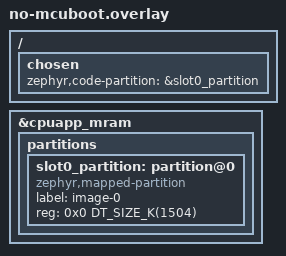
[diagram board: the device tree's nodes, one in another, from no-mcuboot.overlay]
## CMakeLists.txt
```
#
# Copyright (c) 2022 Nordic Semiconductor ASA
#
# SPDX-License-Identifier: LicenseRef-Nordic-5-Clause
#

cmake_minimum_required(VERSION 3.20.0)

find_package(Zephyr REQUIRED HINTS $ENV{ZEPHYR_BASE})
project(nrf_cloud)

# Include certs files if enabled.
zephyr_include_directories_ifdef(CONFIG_NRF_CLOUD_PROVISION_CERTIFICATES certs)

# NORDIC SDK APP START
target_sources(app PRIVATE src/main.c)
target_sources(app PRIVATE src/application.c)
target_sources(app PRIVATE src/cloud_connection.c)
target_sources(app PRIVATE src/message_queue.c)
target_sources(app PRIVATE src/temperature.c)
target_sources(app PRIVATE src/fota_support.c)
target_sources(app PRIVATE src/led_control.c)
target_sources(app PRIVATE src/sample_reboot.c)
target_sources(app PRIVATE src/shadow_config.c)

if(CONFIG_LOCATION_TRACKING)
  target_sources(app PRIVATE src/location_tracking.c)
endif()

if(CONFIG_COAP_SHADOW)
  target_sources(app PRIVATE src/shadow_support_coap.c)
endif()

if(CONFIG_COAP_FOTA)
  target_sources(app PRIVATE src/fota_support_coap.c)
endif()

if(CONFIG_NRF_PROVISIONING)
  target_sources(app PRIVATE src/provisioning_support.c)
endif()

# NORDIC SDK APP END

zephyr_include_directories(src)
zephyr_include_directories(config)
```

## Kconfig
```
#
# Copyright (c) 2022 Nordic Semiconductor ASA
#
# SPDX-License-Identifier: LicenseRef-Nordic-5-Clause
#

menu "Wi-Fi nRF Cloud sample settings"

config APP_VERSION
	string "Wi-Fi nRF Cloud sample version"
	default "1.0.0"

config CLOUD_CONNECTION_RETRY_TIMEOUT_SECONDS
	int "Cloud connection retry timeout (seconds)"
	default 30
	help
	  If connecting to nRF Cloud takes longer than this timeout, it will be
	  reattempted.

config WIFI_CONNECT_RETRY_TIMEOUT_SECONDS
	int "Wi-Fi connection retry timeout (seconds)"
	default 10
	help
	  If a Wi-Fi connection attempt fails, or an established connection is
	  lost, wait this many seconds before requesting a (re)connection.

config CLOUD_READY_TIMEOUT_SECONDS
	int "Cloud readiness timeout (seconds)"
	default 600
	help
	  If the connection to nRF Cloud does not become ready within this
	  timeout, the sample will reset its connection and try again.

config DATE_TIME_ESTABLISHMENT_TIMEOUT_SECONDS
	int "Date and time establishment timeout (seconds)"
	default 300
	help
	  The sample will wait this many seconds for the device to determine the
	  current date and time before giving up and moving on.

config APPLICATION_THREAD_STACK_SIZE
	int "Application Thread Stack Size (bytes)"
	default 2048
	help
	  Sets the stack size (in bytes) for the application thread of the
	  sample.

config CONNECTION_THREAD_STACK_SIZE
	int "Connection Thread Stack Size (bytes)"
	default 2048
	help
	  Sets the stack size (in bytes) for the connection thread of the
	  sample.

config MESSAGE_THREAD_STACK_SIZE
	int "Message Queue Thread Stack Size (bytes)"
	default 2048
	help
	  Sets the stack size (in bytes) for the message queue processing
	  thread of the sample.

config LED_THREAD_STACK_SIZE
	int "LED Thread Stack Size (bytes)"
	default 1024
	help
	  Sets the stack size (in bytes) for the LED thread.

config MAX_OUTGOING_MESSAGES
	int "Outgoing message maximum"
	default 25
	help
	  Sets the maximum number of device messages which may be enqueued
	  before further messages are dropped.
	  Increasing this value may require an increase to CONFIG_HEAP_MEM_POOL_SIZE.

config MAX_CONSECUTIVE_SEND_FAILURES
	int "Max outgoing consecutive send failures"
	default 5
	help
	  Sets the maximum number of device messages which may fail to send
	  before a connection reset and cooldown is triggered.

config CONSECUTIVE_SEND_FAILURE_COOLDOWN_SECONDS
	int "Cooldown after max consecutive send failures exceeded"
	default 10
	help
	  If a connection reset is triggered by too many failed device
	  messages, the sample will wait this long (in seconds) before trying
	  again.

config SENSOR_SAMPLE_INTERVAL_SECONDS
	int "Sensor sampling interval (seconds)"
	default 60
	help
	  Sets the time to wait between each sensor sample.

menuconfig LOCATION_TRACKING
	bool "Location tracking service"
	default y
	help
	  Uses Wi-Fi information to determine and report device location.

if LOCATION_TRACKING

config LOCATION_TRACKING_SAMPLE_INTERVAL_SECONDS
	int "Location sampling interval (seconds)"
	default 60
	help
	  Sets the location sampling interval in seconds.

endif

config TEMP_TRACKING
	bool "Track temperature"
	default y
	help
	  Sets whether to take temperature measurements.

config TEMP_ALERT_LIMIT
	int "Temperature limit to print alert"
	default 30
	help
	  Sets the temperature in degrees C over which a temperature alert will
	  be printed through serial terminal.

choice
	prompt "LED indication"
	default LED_INDICATION_GPIO if $(dt_compat_enabled,gpio-leds)
	default LED_INDICATION_DISABLED

config LED_INDICATION_GPIO
	bool "Enable LED indication using the gpio-leds driver"
	select LED
	select LED_GPIO

config LED_INDICATION_DISABLED
	bool "Disable LED indication"

endchoice

choice
	prompt "LED indication LED type"
	depends on !LED_INDICATION_DISABLED
	default LED_INDICATOR_4LED if !LED_INDICATION_DISABLED
	default LED_INDICATOR_NONE

config LED_INDICATOR_4LED
	bool "Four binary LEDs"
	depends on !LED_INDICATION_DISABLED

config LED_INDICATOR_NONE
	bool "No indicator LEDs"
	depends on LED_INDICATION_DISABLED

endchoice

config LED_VERBOSE_INDICATION
	bool "Enables extra LED status indications"
	depends on !LED_INDICATION_DISABLED
	default y

config LED_CONTINUOUS_INDICATION
	bool "Show an idle pattern instead of turning LEDs off"
	depends on !LED_INDICATION_DISABLED
	default y

config TEST_COUNTER
	bool "Sets whether the test counter is enabled"
	help
	  When enabled, the test counter configuration setting in the shadow is ignored.

config TEST_COUNTER_MULTIPLIER
	int "The number of test counter messages sent on each update"
	default 1
	range 1 1000
	help
	  This is a way to increase the number of device messages sent by the sample.
	  It is useful for load testing.

if NRF_CLOUD_COAP

menuconfig COAP_SHADOW
	bool "Updating shadow service"
	default y
	help
	  Updates the shadow with device information. Checks for a shadow
	  delta periodically and processes it if received.

if COAP_SHADOW

config COAP_SHADOW_CHECK_RATE_SECONDS
	int "Shadow job check interval (seconds)"
	default 300
	help
	  Sets the time to wait between each request to get any change to the
	  device shadow.

config COAP_SHADOW_THREAD_STACK_SIZE
	int "CoAP Shadow Thread Stack Size (bytes)"
	default 3072
	help
	  Sets the stack size (in bytes) for the CoAP shadow thread of the
	  sample.

endif

config COAP_SEND_CONFIRMABLE
	bool "Send device messages as confirmable"
	help
	  Ensures all CoAP transfers, even for often less important messages such
	  as sensor data, are sent as confirmable messages.

endif

endmenu

if NRF_CLOUD_MQTT
module-str = MQTT nRF Cloud
endif
if NRF_CLOUD_COAP
module-str = CoAP nRF Cloud
endif
module = WIFI_NRF_CLOUD
source "$(ZEPHYR_BASE)/subsys/logging/Kconfig.template.log_config"

menu "Zephyr Kernel"
source "Kconfig.zephyr"
endmenu
```

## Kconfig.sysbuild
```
#
# Copyright (c) 2024 Nordic Semiconductor
#
# SPDX-License-Identifier: LicenseRef-Nordic-5-Clause
#

config WIFI_NRF70
	default y if BOARD_NRF7002DK_NRF5340_CPUAPP_NS || \
		BOARD_NRF54L15DK_NRF54L15_CPUAPP || \
		BOARD_NRF54H20DK_NRF54H20_CPUAPP || \
		BOARD_NRF5340DK_NRF5340_CPUAPP_NS || \
		BOARD_NRF54LM20DK_NRF54LM20A_CPUAPP || \
		BOARD_NRF54LM20DK_NRF54LM20B_CPUAPP

source "share/sysbuild/Kconfig"
```

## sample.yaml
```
sample:
  name: Wi-Fi nRF Cloud Sample
tests:
  sample.wifi.conn.mqtt:
    sysbuild: true
    build_only: true
    integration_platforms:
      - nrf7002dk/nrf5340/cpuapp/ns
      - nrf7120dk/nrf7120/cpuapp/ns
    platform_allow:
      - nrf7002dk/nrf5340/cpuapp/ns
      - nrf7120dk/nrf7120/cpuapp/ns
    extra_args:
      - EXTRA_CONF_FILE="mqtt.conf"
    tags:
      - ci_build
      - sysbuild
      - ci_samples_wifi
  sample.wifi.conn.coap.nofota:
    sysbuild: true
    build_only: true
    integration_platforms:
      - nrf7120dk/nrf7120/cpuapp/ns
    platform_allow:
      - nrf7120dk/nrf7120/cpuapp/ns
    extra_args:
      - EXTRA_CONF_FILE="coap.conf"
    tags:
      - ci_build
      - sysbuild
      - ci_samples_wifi
  # Secure-only (no /ns), no FOTA (coap.conf without coap-fota.conf) and no
  # MCUboot (SB_CONFIG_BOOTLOADER_NONE overrides Kconfig.sysbuild's default
  # of MCUboot for this board target). no-mcuboot.overlay is required: the
  # board's default partition layout reserves the first 64 KB of MRAM for
  # MCUboot and links the app to run from slot0_partition at 0x10000, which
  # only works if MCUboot is actually present at 0x0 to jump there. See the
  # overlay file for details.
  sample.wifi.conn.coap.sonly.nofota:
    sysbuild: true
    build_only: true
    integration_platforms:
      - nrf7120dk/nrf7120/cpuapp
    platform_allow:
      - nrf7120dk/nrf7120/cpuapp
    extra_args:
      - EXTRA_CONF_FILE="coap.conf"
      - SB_CONFIG_BOOTLOADER_NONE=y
      - DTC_OVERLAY_FILE="no-mcuboot.overlay"
    tags:
      - ci_build
      - sysbuild
      - ci_samples_wifi
  sample.wifi.conn.coap:
    sysbuild: true
    build_only: true
    integration_platforms:
      - nrf7002dk/nrf5340/cpuapp/ns
      - nrf7120dk/nrf7120/cpuapp
    platform_allow:
      - nrf7002dk/nrf5340/cpuapp/ns
      - nrf7120dk/nrf7120/cpuapp
    extra_args:
      - EXTRA_CONF_FILE="coap.conf;coap-fota.conf"
    tags:
      - ci_build
      - sysbuild
      - ci_samples_wifi
  sample.wifi.conn.nrf7002eb2.mqtt:
    sysbuild: true
    build_only: true
    integration_platforms:
      - nrf54lm20dk/nrf54lm20a/cpuapp/ns
      - nrf54lm20dk/nrf54lm20b/cpuapp/ns
    platform_allow:
      - nrf54lm20dk/nrf54lm20a/cpuapp/ns
      - nrf54lm20dk/nrf54lm20b/cpuapp/ns
    extra_args:
      - SHIELD=nrf7002eb2
      - EXTRA_CONF_FILE="mqtt.conf"
    tags:
      - ci_build
      - sysbuild
      - ci_samples_wifi
  sample.wifi.conn.nrf7002eb2.coap:
    sysbuild: true
    build_only: true
    integration_platforms:
      - nrf54lm20dk/nrf54lm20a/cpuapp/ns
      - nrf54lm20dk/nrf54lm20b/cpuapp/ns
    platform_allow:
      - nrf54lm20dk/nrf54lm20a/cpuapp/ns
      - nrf54lm20dk/nrf54lm20b/cpuapp/ns
    extra_args:
      - SHIELD=nrf7002eb2
      - EXTRA_CONF_FILE="coap.conf;coap-fota.conf"
    tags:
      - ci_build
      - sysbuild
      - ci_samples_wifi
```

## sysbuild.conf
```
#
# Copyright (c) 2024 Nordic Semiconductor
#
# SPDX-License-Identifier: LicenseRef-Nordic-5-Clause
#

# Save flash
SB_CONFIG_BOOTLOADER_NONE=y
SB_CONFIG_BOOTLOADER_MCUBOOT=n
```

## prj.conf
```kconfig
#
# Copyright (c) 2022 Nordic Semiconductor ASA
#
# SPDX-License-Identifier: LicenseRef-Nordic-5-Clause
#

# Log level
# For more verbose and detailed log output, set the log level to
# CONFIG_WIFI_NRF_CLOUD_LOG_LEVEL_DBG=y instead.
CONFIG_WIFI_NRF_CLOUD_LOG_LEVEL_INF=y

# General config
CONFIG_EVENTS=y
CONFIG_PICOLIBC_IO_FLOAT=y
CONFIG_RESET_ON_FATAL_ERROR=y
CONFIG_NCS_SAMPLES_DEFAULTS=y
CONFIG_DK_LIBRARY=y

# Improved Logging
# CONFIG_LOG_MODE_DEFERRED allows logging from multiple threads simultaneously without creating
# splintered log entries, at the cost of needing a buffer for storing logs.
CONFIG_LOG_MODE_DEFERRED=y

# CONFIG_LOG_BUFFER_SIZE is the aforementioned buffer. A size of 4096 bytes is useful for debugging
# and prototyping, but is probably more than necessary for production-ready firmware.
CONFIG_LOG_BUFFER_SIZE=4096

# Heap and stacks
# Extended memory heap size needed for Wi-Fi operation and encoding JSON-based nRF Cloud Device Messages.
# Add 256 bytes for each additional scanning result (CONFIG_NRF_WIFI_SCAN_MAX_BSS_CNT),
# assuming sane SSID lengths.
CONFIG_HEAP_MEM_POOL_SIZE=40144
CONFIG_HEAP_MEM_POOL_IGNORE_MIN=y
CONFIG_SYSTEM_WORKQUEUE_STACK_SIZE=4096
CONFIG_MAIN_STACK_SIZE=2048

# Enable Networking and Connection Manager.
CONFIG_NETWORKING=y
CONFIG_NET_SOCKETS=y
CONFIG_NET_SOCKETS_OFFLOAD=n
CONFIG_NET_MGMT_EVENT_QUEUE_SIZE=30
CONFIG_NET_CONNECTION_MANAGER_MONITOR_STACK_SIZE=6144
CONFIG_NET_CONNECTION_MANAGER=y

CONFIG_NET_IPV4=y
CONFIG_NET_IPV6=y
CONFIG_NET_IPV6_NBR_CACHE=n
CONFIG_NET_IPV6_MLD=n

# DNS
CONFIG_DNS_RESOLVER=y
CONFIG_NET_SOCKETS_DNS_TIMEOUT=30000

# Wi-Fi drivers (nRF70x)
CONFIG_WIFI=y
CONFIG_WIFI_NRF70=y
CONFIG_WIFI_NRF70_SKIP_LOCAL_ADMIN_MAC=y

# Wi-Fi conn_mgr bindings
CONFIG_L2_WIFI_CONNECTIVITY=y
CONFIG_L2_WIFI_CONNECTIVITY_AUTO_CONNECT=y

# Wi-Fi credentials (simplified Wi-Fi connection setup)
CONFIG_WIFI_CREDENTIALS=y

# Wi-Fi networking and native networking stack
# Note: WIFI_NM_WPA_SUPPLICANT requires 24kB of unused RAM in the final build.
# Memory allocations are fine-tuned with that fact in mind.
CONFIG_WIFI_NM_WPA_SUPPLICANT=y
CONFIG_NET_L2_ETHERNET=y
CONFIG_NET_NATIVE=y
CONFIG_NET_SOCKETS_SOCKOPT_TLS=y
CONFIG_NET_CONTEXT_SNDTIMEO=y
CONFIG_NET_TCP=y
CONFIG_NET_DHCPV4=y

# MBEDTLS base configuration for Wi-Fi TLS/DTLS
CONFIG_MBEDTLS=y
CONFIG_MBEDTLS_ENABLE_HEAP=y
CONFIG_MBEDTLS_SSL_SERVER_NAME_INDICATION=y
CONFIG_MBEDTLS_HEAP_SIZE=80000
# PEM parsing is required for TLS credentials provisioned via the shell
CONFIG_MBEDTLS_PEM_PARSE_C=y
# Ciphersuite for MQTT
CONFIG_MBEDTLS_CIPHERSUITE_TLS_ECDHE_RSA_WITH_AES_128_CBC_SHA256=y
CONFIG_PSA_WANT_ALG_ECDSA=y
# PBKDF2-HMAC is needed for WPA2-PSK passphrase hashing (pbkdf2_sha1)
CONFIG_PSA_WANT_ALG_PBKDF2_HMAC=y
CONFIG_PSA_WANT_ALG_PBKDF2_AES_CMAC_PRF_128=y

# Wait for credential installation to be complete before connecting to nRF Cloud
CONFIG_NRF_CLOUD_CHECK_CREDENTIALS=y

# nRF Cloud
CONFIG_NRF_CLOUD=y
CONFIG_NRF_CLOUD_MQTT=y

# Use compile-time client ID for nRF Cloud
CONFIG_NRF_CLOUD_CLIENT_ID_SRC_HW_ID=y
CONFIG_HW_ID_LIBRARY=y
CONFIG_HW_ID_LIBRARY_SOURCE_DEVICE_ID=y

# Location Services configuration
CONFIG_LOCATION=y
CONFIG_NRF_CLOUD_LOCATION=y
CONFIG_LOCATION_METHOD_WIFI=y
# Keep CONFIG_NRF_WIFI_SCAN_MAX_BSS_CNT and CONFIG_LOCATION_METHOD_WIFI_SCANNING_RESULTS_MAX_CNT
# set to the same value.
CONFIG_NRF_WIFI_SCAN_MAX_BSS_CNT=10
CONFIG_LOCATION_METHOD_WIFI_SCANNING_RESULTS_MAX_CNT=10

# Date Time lib - Used by main application
CONFIG_DATE_TIME=y
# Enable date_time retries for Wi-Fi
# This prevents occasional DNS lookup flukes from
# rendering the device unable to connect until the next
# CONFIG_DATE_TIME_UPDATE_INTERVAL_SECONDS elapses (default 4 hours)
CONFIG_DATE_TIME_RETRY_COUNT=5
# Use a really short retry interval for demo purposes
# 60 seconds to 15 minutes is probably more appropriate for real-world applications
CONFIG_DATE_TIME_RETRY_INTERVAL_SECONDS=20

# Settings - NVS is used (required by WIFI_CREDENTIALS)
CONFIG_SETTINGS=y
CONFIG_SETTINGS_NVS=y
CONFIG_NVS=y

# Flash
CONFIG_FLASH=y
CONFIG_FLASH_PAGE_LAYOUT=y
CONFIG_FLASH_MAP=y

# TFM and Trusted Execution (required for Protected Storage credential management)
# Note: even when using Protected Storage, credentials are still retrieved into insecure
# memory when in use.
CONFIG_BUILD_WITH_TFM=y
CONFIG_TRUSTED_EXECUTION_NONSECURE=y
CONFIG_TFM_PARTITION_PROTECTED_STORAGE=y
# The NOT_SET profile enables all features; we reduce some settings below to save flash and RAM.
CONFIG_TFM_PROFILE_TYPE_NOT_SET=y
CONFIG_TFM_CRYPTO_ASYM_SIGN_MODULE_ENABLED=y

# Credential management shells
CONFIG_SHELL=y
CONFIG_NET_L2_WIFI_SHELL=y
CONFIG_WIFI_CREDENTIALS_SHELL=y
CONFIG_TLS_CREDENTIALS_SHELL=y
# "net iface" shows MAC + IP; "net ping" useful for connectivity checks
CONFIG_NET_SHELL=y
CONFIG_DEVMEM_SHELL=n
CONFIG_TLS_CREDENTIALS_BACKEND_PROTECTED_STORAGE=y
# Increased stack size needed for wifi_cred auto_connect command
CONFIG_SHELL_STACK_SIZE=6144
# nRFCloud credentials can exceed 1024 bytes
CONFIG_TLS_CREDENTIALS_SHELL_CRED_BUF_SIZE=3072
# Needed by the TLS credentials shell
CONFIG_BASE64=y

# Miscellaneous resource allocation tweaks needed to support Wi-Fi
CONFIG_MESSAGE_THREAD_STACK_SIZE=2048
CONFIG_CONNECTION_THREAD_STACK_SIZE=6144
CONFIG_DATE_TIME_THREAD_STACK_SIZE=2048
CONFIG_NET_TX_STACK_SIZE=1024
CONFIG_NET_RX_STACK_SIZE=2048
CONFIG_WIFI_NM_WPA_SUPPLICANT_THREAD_STACK_SIZE=6144
CONFIG_LOCATION_WORKQUEUE_STACK_SIZE=2048
CONFIG_ZVFS_POLL_MAX=8

## TF-M: keep IPC mode (default) for the MQTT build. Enable MM-IOVEC to save RAM.
CONFIG_TFM_PSA_FRAMEWORK_HAS_MM_IOVEC=y

## Re-enable IPv6 neighbor cache and MLD (disabled above by default)
CONFIG_NET_IPV6_NBR_CACHE=y
CONFIG_NET_IPV6_MLD=y

## Configure MBEDTLS for MQTT/TLS (CoAP overlay overrides these)
CONFIG_MQTT_LIB_TLS=y
CONFIG_MBEDTLS_SSL_SRV_C=n
CONFIG_MBEDTLS_SSL_COOKIE_C=n

## nRF700x memory allocation (CoAP overlay overrides these)
CONFIG_NRF_WIFI_CTRL_HEAP_SIZE=15000
CONFIG_NRF_WIFI_DATA_HEAP_SIZE=97856

## Thread stack sizes (CoAP overlay overrides APPLICATION_THREAD, NET_MGMT_EVENT, CONNECTION_THREAD)
CONFIG_APPLICATION_THREAD_STACK_SIZE=2048
CONFIG_NET_MGMT_EVENT_STACK_SIZE=8192

# Enable key generation for nRF Cloud credentials on device, and the associated shell command.
CONFIG_NRF_CLOUD_CREDENTIALS_KEYGEN=y
CONFIG_NRF_CLOUD_CREDENTIALS_KEYGEN_SHELL=y
```

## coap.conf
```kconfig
#
# Copyright (c) 2024 Nordic Semiconductor ASA
#
# SPDX-License-Identifier: LicenseRef-Nordic-5-Clause
#

## TF-M: SFN mode with MM-IOVEC (see prj.conf) to keep RAM usage down for CoAP.
CONFIG_TFM_IPC=n
CONFIG_TFM_SFN=y
CONFIG_TFM_CRYPTO_CONC_OPER_NUM=4

## Additional date_time settings for CoAP
CONFIG_DATE_TIME_NTP=y
CONFIG_DATE_TIME_LOG_LEVEL_DBG=y

## Configure MBEDTLS for CoAP/DTLS
CONFIG_MQTT_LIB_TLS=n
CONFIG_MBEDTLS_DTLS=y
CONFIG_MBEDTLS_SSL_SRV_C=y
CONFIG_MBEDTLS_SSL_COOKIE_C=y
# Ciphersuite for CoAP
CONFIG_MBEDTLS_CIPHERSUITE_TLS_ECDHE_ECDSA_WITH_AES_128_GCM_SHA256=y
CONFIG_MBEDTLS_SSL_DTLS_HELLO_VERIFY=y
CONFIG_MBEDTLS_SSL_DTLS_CONNECTION_ID=y
CONFIG_NET_SOCKETS_ENABLE_DTLS=y

## Memory allocation
CONFIG_NRF_WIFI_CTRL_HEAP_SIZE=20000
CONFIG_NRF_WIFI_DATA_HEAP_SIZE=92856

## Thread stack sizes

CONFIG_APPLICATION_THREAD_STACK_SIZE=4096
CONFIG_CONNECTION_THREAD_STACK_SIZE=6144
CONFIG_NET_MGMT_EVENT_STACK_SIZE=8192
CONFIG_WIFI_NM_WPA_SUPPLICANT_THREAD_STACK_SIZE=6144
CONFIG_NET_CONNECTION_MANAGER_MONITOR_STACK_SIZE=5120
CONFIG_NET_TX_STACK_SIZE=1024
CONFIG_NET_RX_STACK_SIZE=2048
CONFIG_LOCATION_WORKQUEUE_STACK_SIZE=4096

# nRF Cloud: CoAP
CONFIG_NRF_CLOUD_MQTT=n
CONFIG_NRF_CLOUD_COAP=y
CONFIG_NRF_CLOUD_LOCATION=n
CONFIG_NRF_CLOUD_JWT_SOURCE_CUSTOM=y

# General config
CONFIG_FPU=y

# Rate of cloud interactions
# These are faster than one normally would use in a low power device.
# This is strictly for demo purposes.
CONFIG_SENSOR_SAMPLE_INTERVAL_SECONDS=120
CONFIG_LOCATION_TRACKING_SAMPLE_INTERVAL_SECONDS=360

# Logs
CONFIG_NET_LOG=y
CONFIG_LOG_PRINTK=y
CONFIG_COAP_LOG_LEVEL_INF=y
CONFIG_LOCATION_LOG_LEVEL_INF=y

# Network
CONFIG_POSIX_API=y
CONFIG_NET_SOCKETS_TLS_SET_MAX_FRAGMENT_LENGTH=y
CONFIG_NET_SOCKETS_OFFLOAD_PRIORITY=40

# CoAP Client
CONFIG_COAP_CLIENT_BLOCK_SIZE=1024
CONFIG_COAP_CLIENT_STACK_SIZE=3072
CONFIG_COAP_CLIENT_THREAD_PRIORITY=0
CONFIG_COAP_EXTENDED_OPTIONS_LEN_VALUE=40
# Wi-Fi RTT to nRF Cloud can be high; give CON transfers more time.
CONFIG_COAP_INIT_ACK_TIMEOUT_MS=4000
CONFIG_COAP_MAX_RETRANSMIT=8

# Location Services configuration
CONFIG_LOCATION_DATA_DETAILS=n

CONFIG_TEMP_ALERT_LIMIT=24

# Disabling to prevent IPv6 error logs
CONFIG_NET_IPV6=n
CONFIG_NET_IPV6_NBR_CACHE=n
CONFIG_NET_IPV6_MLD=n
```

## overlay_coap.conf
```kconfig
#
# Copyright (c) 2024 Nordic Semiconductor ASA
#
# SPDX-License-Identifier: LicenseRef-Nordic-5-Clause
#

## Disable CoAP FOTA
CONFIG_COAP_FOTA=n

## TFM: select SFN mode for faster crypto in CoAP builds
CONFIG_TFM_IPC=n
CONFIG_TFM_SFN=y
CONFIG_TFM_CRYPTO_CONC_OPER_NUM=4

## Additional date_time settings for CoAP
CONFIG_DATE_TIME_NTP=y
CONFIG_DATE_TIME_LOG_LEVEL_DBG=y

## Configure MBEDTLS for CoAP/DTLS
CONFIG_MQTT_LIB_TLS=n
CONFIG_MBEDTLS_DTLS=y
CONFIG_MBEDTLS_SSL_SRV_C=y
CONFIG_MBEDTLS_SSL_COOKIE_C=y
CONFIG_MBEDTLS_SSL_DTLS_HELLO_VERIFY=y
CONFIG_MBEDTLS_SSL_DTLS_CONNECTION_ID=y
CONFIG_NET_SOCKETS_ENABLE_DTLS=y

# Keep legacy hostap crypto on nRF5340 NS Wi-Fi CoAP builds.
# If we use HOSTAP_CRYPTO_ALT_PSA, hostap selects MBEDTLS_USE_PSA_CRYPTO,
# which routes mbedTLS TLS/X.509 through PSA/TF-M and can break DTLS connect
# to coap.nrfcloud.com (observed as zsock_connect() failure: -111 / ECONNREFUSED).
# Legacy mode keeps the non-PSA mbedTLS TLS path and restores stable cloud connection.
CONFIG_HOSTAP_CRYPTO_ALT_LEGACY_PSA=y

## Memory allocation
CONFIG_NRF_WIFI_CTRL_HEAP_SIZE=20000
CONFIG_NRF_WIFI_DATA_HEAP_SIZE=92856

## Thread stack sizes
CONFIG_APPLICATION_THREAD_STACK_SIZE=8192
CONFIG_NET_MGMT_EVENT_STACK_SIZE=8000

# nRF Cloud: CoAP
CONFIG_NRF_CLOUD_MQTT=n
CONFIG_NRF_CLOUD_COAP=y
CONFIG_NRF_CLOUD_LOCATION=n
CONFIG_NRF_CLOUD_JWT_SOURCE_CUSTOM=y

# General config
CONFIG_FPU=y

# Rate of cloud interactions
# These are faster than one normally would use in a low power device.
# This is strictly for demo purposes.
CONFIG_SENSOR_SAMPLE_INTERVAL_SECONDS=120
CONFIG_LOCATION_TRACKING_SAMPLE_INTERVAL_SECONDS=360

# Logs
CONFIG_NET_LOG=y
CONFIG_LOG_PRINTK=y
CONFIG_COAP_LOG_LEVEL_INF=y
CONFIG_LOCATION_LOG_LEVEL_INF=y

# Network
CONFIG_POSIX_API=y
CONFIG_NET_SOCKETS_TLS_SET_MAX_FRAGMENT_LENGTH=y
CONFIG_NET_SOCKETS_OFFLOAD_PRIORITY=40

# CoAP Client
CONFIG_COAP_CLIENT_BLOCK_SIZE=1024
CONFIG_COAP_CLIENT_STACK_SIZE=6144
CONFIG_COAP_CLIENT_THREAD_PRIORITY=0
CONFIG_COAP_EXTENDED_OPTIONS_LEN_VALUE=40
# Wi-Fi RTT to nRF Cloud can be high; give CON transfers more time.
CONFIG_COAP_INIT_ACK_TIMEOUT_MS=4000
CONFIG_COAP_MAX_RETRANSMIT=8

# Location Services configuration
CONFIG_LOCATION_DATA_DETAILS=n

CONFIG_TEMP_ALERT_LIMIT=24

# Disabling to prevent IPv6 error logs
CONFIG_NET_IPV6=n
```

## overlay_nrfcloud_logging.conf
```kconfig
#
# Copyright (c) 2023 Nordic Semiconductor ASA
#
# SPDX-License-Identifier: LicenseRef-Nordic-5-Clause
#
CONFIG_NRF_CLOUD_LOG_BACKEND=y
CONFIG_NRF_CLOUD_LOG_OUTPUT_LEVEL=3
CONFIG_NRF_CLOUD_LOG_LOG_LEVEL_INF=y
CONFIG_LOG_MODE_DEFERRED=y
CONFIG_NRF_CLOUD_LOG_INCLUDE_LEVEL_0=y

# If enabled, log levels for each log source can be set per log backend, and
# can be changed dynamically.
CONFIG_LOG_RUNTIME_FILTERING=n

CONFIG_LOG_BUFFER_SIZE=4096

# Select which format to generate. Dictionary logs are compact but require
# decoding on the server or user PC. Text logs are verbose but immediately
# visible in the nRF Cloud web portal. Unless you disable UART text logging,
# you must set CONFIG_LOG_FMT_SECTION_STRIP=n when
# CONFIG_LOG_BACKEND_NRF_CLOUD_OUTPUT_DICTIONARY=y, or else you will get a
# build assert warning you to do so. This is to prevent a hard crash at runtime.
CONFIG_LOG_BACKEND_NRF_CLOUD_OUTPUT_TEXT=y
#CONFIG_LOG_BACKEND_NRF_CLOUD_OUTPUT_DICTIONARY=y
#CONFIG_LOG_FMT_SECTION_STRIP=n

CONFIG_LOG_PROCESS_THREAD_STACK_SIZE=4096
CONFIG_LOG_PROCESS_THREAD_SLEEP_MS=30000
```

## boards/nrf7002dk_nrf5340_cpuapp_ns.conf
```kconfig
#
# Copyright (c) 2026 Nordic Semiconductor ASA
#
# SPDX-License-Identifier: LicenseRef-Nordic-5-Clause
#

# nRF Cloud credentials
CONFIG_NRF_CLOUD_PROVISION_CERTIFICATES=y
CONFIG_NRF_CLOUD_CLIENT_ID_SRC_COMPILE_TIME=y
CONFIG_NRF_CLOUD_CLIENT_ID="216c393d-b529-4eb5-a2a7-987d5a8ae68a"

# Enable LTO to save flash memory (required for CoAP overlay which would otherwise overflow)
CONFIG_LTO=y
CONFIG_ISR_TABLES_LOCAL_DECLARATION=y
```

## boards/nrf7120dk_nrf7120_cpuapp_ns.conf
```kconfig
#
# Copyright (c) 2026 Nordic Semiconductor ASA
#
# SPDX-License-Identifier: LicenseRef-Nordic-5-Clause
#

# IOVEC would conflict with TFM_ITS_ENCRYPTED, which we want to keep
# as default for higher security.
CONFIG_TFM_PSA_FRAMEWORK_HAS_MM_IOVEC=n
# Necessary for TLS with MM-less IOVEC
CONFIG_TFM_CRYPTO_IOVEC_BUFFER_SIZE=36864
# pk_wrap.c uses PSA_ALG_ECDSA_ANY (pre-hashed ECDSA) for X.509 certificate
# chain verification
CONFIG_PSA_WANT_ALG_ECDSA_ANY=y

# FOTA requires MCUBoot; this sample uses BOOTLOADER_NONE on nrf7120dk.
# Disabling NRF_CLOUD_FOTA also avoids pulling in FW_INFO, which has no
# SOC_SERIES_NRF71 defaults and causes both a CMake and a linker error.
CONFIG_NRF_CLOUD_FOTA=n

# nRF7120 _ns/TF-M has no Zephyr flash driver (so no NVS), but it does have TF-M
# PSA secure storage. Use the PSA settings backend: settings are kept in RAM and
# persisted via TF-M PSA ITS, so settings init and the MQTT session-state save
# both succeed -- no need to disable settings or force a clean session.
CONFIG_SETTINGS_TFM_PSA=y
```

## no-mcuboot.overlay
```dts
/*
 * Copyright (c) 2026 Nordic Semiconductor ASA
 *
 * SPDX-License-Identifier: LicenseRef-Nordic-5-Clause
 */

/*
 * nrf7120dk/nrf7120/cpuapp's default partition layout (see
 * nordic/nrf7120_cpuapp_partition.dtsi) reserves the first 64 KB of MRAM for
 * MCUboot (boot_partition) and links the application to run from
 * slot0_partition at offset 0x10000. That only works with MCUboot actually
 * present at address 0 to jump into slot0 -- with
 * -DSB_CONFIG_BOOTLOADER_NONE=y no bootloader is built, so nothing would ever
 * reach the application at 0x10000 and the device would not boot.
 *
 * Merge boot_partition into slot0_partition so the single, non-upgradable
 * application image is linked to run directly from address 0x0 instead.
 * slot1_partition/storage_partition are untouched (slot0 still ends exactly
 * where slot1 begins, at 0x178000).
 *
 * Note: nrf7120dk_nrf7120_cpuapp_defconfig unconditionally sets
 * CONFIG_FLASH_LOAD_OFFSET=0xA000, a fixed SoC-level boot offset applied on
 * top of whatever address the code-partition starts at (regardless of
 * MCUboot). With this overlay the application therefore actually starts at
 * 0xA000 (0x0 + 0xA000), instead of 0x1A000 (0x10000 + 0xA000) as it would
 * without the overlay -- which lands inside the otherwise-empty
 * boot_partition gap and would never run without a bootloader there.
 */
/delete-node/ &boot_partition;
/delete-node/ &slot0_partition;

&cpuapp_mram {
	partitions {
		slot0_partition: partition@0 {
			compatible = "zephyr,mapped-partition";
			label = "image-0";
			reg = <0x0 DT_SIZE_K(1504)>;
		};
	};
};

/ {
	chosen {
		zephyr,code-partition = &slot0_partition;
	};
};
```

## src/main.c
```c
/* Copyright (c) 2023 Nordic Semiconductor ASA
 *
 * SPDX-License-Identifier: LicenseRef-Nordic-5-Clause
 */

#include <zephyr/kernel.h>
#include <stdio.h>
#include <zephyr/logging/log.h>
#include "application.h"
#include "cloud_connection.h"
#include "message_queue.h"
#include "led_control.h"
#if defined(CONFIG_NRF_CLOUD_COAP)
#include "fota_support_coap.h"
#include "shadow_support_coap.h"
#endif

LOG_MODULE_REGISTER(main, CONFIG_WIFI_NRF_CLOUD_LOG_LEVEL);

/* Here, we start the various threads that our application will run in */

#ifndef CONFIG_LED_INDICATION_DISABLED
/* Define, and automatically start the LED animation thread. See led_control.c */
K_THREAD_DEFINE(led_thread, CONFIG_LED_THREAD_STACK_SIZE, led_animation_thread_fn,
		NULL, NULL, NULL, 0, 0, 0);
#endif

/* Define, and automatically start the main application thread. See application.c */
K_THREAD_DEFINE(app_thread, CONFIG_APPLICATION_THREAD_STACK_SIZE, main_application_thread_fn,
		NULL, NULL, NULL, 0, 0, 0);

/* Define, and automatically start the message queue thread. See message_queue.c */
K_THREAD_DEFINE(msg_thread, CONFIG_MESSAGE_THREAD_STACK_SIZE, message_queue_thread_fn,
		NULL, NULL, NULL, 0, 0, 0);

/* Define, and automatically start the cloud connection thread. See cloud_connection.c */
K_THREAD_DEFINE(con_thread, CONFIG_CONNECTION_THREAD_STACK_SIZE, cloud_connection_thread_fn,
		NULL, NULL, NULL, 0, 0, 0);

#if defined(CONFIG_NRF_CLOUD_COAP)
#if defined(CONFIG_COAP_FOTA)
/* Define, and automatically start the CoAP FOTA check thread. See fota_support_coap.c */
K_THREAD_DEFINE(coap_fota, CONFIG_COAP_FOTA_THREAD_STACK_SIZE, coap_fota_thread_fn,
		NULL, NULL, NULL, 0, 0, 0);
#endif

#if defined(CONFIG_COAP_SHADOW)
/* Define, and automatically start the CoAP shadow check thread. See shadow_support_coap.c */
K_THREAD_DEFINE(coap_shadow, CONFIG_COAP_SHADOW_THREAD_STACK_SIZE, coap_shadow_thread_fn,
		NULL, NULL, NULL, 0, 0, 0);
#endif
#endif /* CONFIG_NRF_CLOUD_COAP */

/* main() is called from the main thread, which defaults to priority zero,
 * but for illustrative purposes we don't use it. main_application() could be called directly
 * from this function, rather than given its own dedicated thread.
 */
int main(void)
{
	const char *protocol;

	if (IS_ENABLED(CONFIG_NRF_CLOUD_MQTT)) {
		protocol = "MQTT";
	} else if (IS_ENABLED(CONFIG_NRF_CLOUD_COAP)) {
		protocol = "CoAP";
	}

	LOG_INF("WiFi nRF Cloud sample has started, version: %s, protocol: %s",
		CONFIG_APP_VERSION, protocol);

	return 0;
}
```

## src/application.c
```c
/* Copyright (c) 2023 Nordic Semiconductor ASA
 *
 * SPDX-License-Identifier: LicenseRef-Nordic-5-Clause
 */

#include <zephyr/kernel.h>
#include <zephyr/logging/log.h>
#include <zephyr/logging/log_ctrl.h>
#include <helpers/nrfx_reset_reason.h>
#include <date_time.h>
#include <stdio.h>
#include <net/nrf_cloud.h>
#include <net/nrf_cloud_codec.h>
#include <net/nrf_cloud_log.h>
#if defined(CONFIG_NRF_CLOUD_COAP)
#include <net/nrf_cloud_coap.h>
#endif
#if defined(CONFIG_LOCATION_TRACKING)
#include <modem/location.h>
#include "location_tracking.h"
#endif
#include <dk_buttons_and_leds.h>
#include "application.h"
#include "temperature.h"
#include "cloud_connection.h"
#include "message_queue.h"
#include "led_control.h"
#include "shadow_config.h"
#if IS_ENABLED(CONFIG_MEMFAULT) && IS_ENABLED(CONFIG_NRF_CLOUD_COAP)
#include <memfault/core/trace_event.h>
#endif

LOG_MODULE_REGISTER(application, CONFIG_WIFI_NRF_CLOUD_LOG_LEVEL);

/* Timer used to time the sensor sampling rate. */
static K_TIMER_DEFINE(sensor_sample_timer, NULL, NULL);

/* Temperature alert limits. */
#define TEMP_ALERT_LIMIT ((double)CONFIG_TEMP_ALERT_LIMIT)
#define TEMP_ALERT_HYSTERESIS 1.5
#define TEMP_ALERT_LOWER_LIMIT (TEMP_ALERT_LIMIT - TEMP_ALERT_HYSTERESIS)

/* State of the test counter. This can be changed using the configuration in the shadow */
static bool test_counter_enabled;

/**
 * @brief Construct a device message object with automatically generated timestamp
 *
 * The resultant JSON object will be conformal to the General Message Schema described in the
 * application-protocols repo:
 *
 * https://github.com/nRFCloud/application-protocols
 *
 * @param msg - The object to contain the message
 * @param appid - The appId for the device message
 * @param msg_type - The messageType for the device message
 * @return int - 0 on success, negative error code otherwise.
 */
static int create_timestamped_device_message(struct nrf_cloud_obj *const msg,
					     const char *const appid,
					     const char *const msg_type)
{
	int err;
	int64_t timestamp;

	/* Acquire timestamp */
	err = date_time_now(&timestamp);
	if (err) {
		LOG_ERR("Failed to obtain current time, error %d", err);
		return -ETIME;
	}

	/* Create message object */
	err = nrf_cloud_obj_msg_init(msg, appid,
				     IS_ENABLED(CONFIG_NRF_CLOUD_COAP) ? NULL : msg_type);
	if (err) {
		LOG_ERR("Failed to initialize message with appid %s and msg type %s",
			appid, msg_type);
		return err;
	}

	/* Add timestamp to message object */
	err = nrf_cloud_obj_ts_add(msg, timestamp);
	if (err) {
		LOG_ERR("Failed to add timestamp to data message with appid %s and msg type %s",
			appid, msg_type);
		nrf_cloud_obj_free(msg);
		return err;
	}

	return 0;
}

/**
 * @brief Transmit a collected sensor sample to nRF Cloud.
 *
 * @param sensor - The name of the sensor which was sampled.
 * @param value - The sampled sensor value.
 * @return int - 0 on success, negative error code otherwise.
 */
static int send_sensor_sample(const char *const sensor, double value)
{
	int ret;

	MSG_OBJ_DEFINE(msg_obj);

	/* Create a timestamped message container object for the sensor sample. */
	ret = create_timestamped_device_message(&msg_obj, sensor,
						NRF_CLOUD_JSON_MSG_TYPE_VAL_DATA);
	if (ret) {
		return -EINVAL;
	}

	/* Populate the container object with the sensor value. */
	ret = nrf_cloud_obj_num_add(&msg_obj, NRF_CLOUD_JSON_DATA_KEY, value, false);
	if (ret) {
		LOG_ERR("Failed to append value to %s sample container object ",
			sensor);
		nrf_cloud_obj_free(&msg_obj);
		return -ENOMEM;
	}

	/* Send the sensor sample container object as a device message. */
	return send_device_message(&msg_obj);
}

#if defined(CONFIG_LOCATION_TRACKING)
/**
 * @brief Callback to receive periodic location updates from location_tracking.c and forward them
 * to nRF Cloud.
 *
 * @param location_data - The received location update.
 *
 */
static void on_location_update(const struct location_event_data * const location_data)
{
	LOG_INF("Location Updated: lat: %.06f, lon: %.06f, accuracy: %.01f m, Method: %s",
		location_data->location.latitude,
		location_data->location.longitude,
		(double)location_data->location.accuracy,
		location_method_str(location_data->method));
}
#endif /* CONFIG_LOCATION_TRACKING */

/** @brief Check whether temperature is acceptable.
 * If the device exceeds a temperature limit, log a warning and send the temperature_alert
 * Trace Event one time (when Memfault with CoAP is enabled).
 * Once the temperature falls below a lower limit, re-enable the temperature alert
 * so it will be sent if the limit is exceeded again.
 *
 * The difference between the two limits should be sufficient to prevent sending
 * a new Trace Event if the temperature value oscillates between two nearby values.
 *
 * @param temp - The current device temperature.
 */
static void monitor_temperature(double temp)
{
	static bool temperature_alert_active;

	if ((temp > TEMP_ALERT_LIMIT) && !temperature_alert_active) {
		temperature_alert_active = true;
		LOG_INF("Temperature limit %f C exceeded: now %f C.",
			TEMP_ALERT_LIMIT, temp);
		#if defined(CONFIG_MEMFAULT) && defined(CONFIG_NRF_CLOUD_COAP)
			/* When using nRF Cloud powered by Memfault, send a Trace Event when the
			 * temperature limit is exceeded.
			 */
			MEMFAULT_TRACE_EVENT_WITH_LOG(temperature_alert,
				"Alert! Temperature is: %.2f C", temp);
		#endif
	} else if ((temp < TEMP_ALERT_LOWER_LIMIT) && temperature_alert_active) {
		temperature_alert_active = false;
		LOG_INF("Temperature now below limit: %f C.", temp);
	}
}

/** @brief Send an incrementing test counter message to nRF Cloud.
 * If CONFIG_TEST_COUNTER_MULTIPLIER is greater than 1, the counter will be incremented
 * that many times in a row, and a separate test counter message will be sent for each increment.
 */
static void test_counter_send(void)
{
	static int counter;

	for (int i = 0; i < CONFIG_TEST_COUNTER_MULTIPLIER; i++) {
		LOG_INF("Sent test counter = %d", counter);
		(void)send_sensor_sample("COUNT", counter++);
	}
}

#if defined(CONFIG_DK_LIBRARY)
static void button_handler(uint32_t button_state, uint32_t has_changed)
{
	if (has_changed & DK_BTN1_MSK) {
		if ((button_state & DK_BTN1_MSK) == DK_BTN1_MSK) {
			LOG_INF("Button pressed");
		}
	}
}
#endif

static void print_reset_reason(void)
{
	uint32_t reset_reason;

	reset_reason = nrfx_reset_reason_get();
	nrfx_reset_reason_clear(reset_reason);
	LOG_INF("Reset reason: 0x%x", reset_reason);
}

void main_application_thread_fn(void)
{
	print_reset_reason();

#if defined(CONFIG_DK_LIBRARY)
	dk_buttons_init(button_handler);
#endif

	/* Wait for first connection before starting the application. */
	(void)await_cloud_ready(K_FOREVER);

	/* Wait for the date and time to become known.
	 * This is needed both for location services and for sensor sample timestamping.
	 */
	LOG_INF("Waiting for device to determine current date and time");
	if (!await_date_time_known(K_SECONDS(CONFIG_DATE_TIME_ESTABLISHMENT_TIMEOUT_SECONDS))) {
		LOG_WRN("Failed to determine valid date time. Proceeding anyways");
	} else {
		LOG_INF("Current date and time determined");
	}

	const char *protocol = "";

	if (IS_ENABLED(CONFIG_NRF_CLOUD_MQTT)) {
		protocol = "MQTT";
	} else if (IS_ENABLED(CONFIG_NRF_CLOUD_COAP)) {
		protocol = "CoAP";
	}
	nrf_cloud_log_init();
	nrf_cloud_log_control_set(CONFIG_NRF_CLOUD_LOG_OUTPUT_LEVEL);
	/* Send a direct log to the nRF Cloud web portal indicating the sample has started up. */
	(void)nrf_cloud_log_send(LOG_LEVEL_INF,
				 "WiFi nRF Cloud sample has started, "
				 "version: %s, protocol: %s",
				 CONFIG_APP_VERSION, protocol);

#if defined(CONFIG_LOCATION_TRACKING)
	/* Begin tracking location at the configured interval. */
	(void)start_location_tracking(on_location_update,
					CONFIG_LOCATION_TRACKING_SAMPLE_INTERVAL_SECONDS);
#endif

	/* Begin sampling sensors. */
	while (true) {
		/* Start the sensor sample interval timer.
		 * We use a timer here instead of merely sleeping the thread, because the
		 * application thread can be preempted by other threads performing long tasks
		 * (such as periodic location acquisition), and we want to account for these
		 * delays when metering the sample send rate.
		 */
		k_timer_start(&sensor_sample_timer,
			K_SECONDS(CONFIG_SENSOR_SAMPLE_INTERVAL_SECONDS), K_FOREVER);

		if (IS_ENABLED(CONFIG_TEMP_TRACKING)) {
			double temp = -1;

			if (get_temperature(&temp) == 0) {
				LOG_INF("Temperature is %d degrees C", (int)temp);
				(void)send_sensor_sample(NRF_CLOUD_JSON_APPID_VAL_TEMP, temp);

				monitor_temperature(temp);
			}
		}

		if (test_counter_enable_get()) {
			test_counter_send();
		}

		/* Wait out any remaining time on the sample interval timer. */
		k_timer_status_sync(&sensor_sample_timer);

		/* If cloud stops being ready due to network trouble or device being deleted
		 * from the cloud, turn off sensors and wait, then restart sensors.
		 */
		if (!await_cloud_ready(K_NO_WAIT) && is_device_deleted()) {
#if defined(CONFIG_LOCATION_TRACKING)
			(void)location_request_cancel();
#endif
			LOG_INF("Cloud not ready. Pausing sensors.");
			(void)await_cloud_ready(K_FOREVER);
			LOG_INF("Cloud is ready. Enabling sensors.");
#if defined(CONFIG_LOCATION_TRACKING)
			/* Begin tracking location at the configured interval. */
			(void)start_location_tracking(on_location_update,
						  CONFIG_LOCATION_TRACKING_SAMPLE_INTERVAL_SECONDS);
#endif
		}
	}
}

void test_counter_enable_set(const bool enable)
{
	if (IS_ENABLED(CONFIG_TEST_COUNTER)) {
		LOG_DBG("CONFIG_TEST_COUNTER is enabled, ignoring state change request");
	} else {
		LOG_DBG("Test counter %s", enable ? "enabled" : "disabled");
		test_counter_enabled = enable;
	}
}

bool test_counter_enable_get(void)
{
	/* When CONFIG_TEST_COUNTER is enabled the test counter is always enabled */
	return (test_counter_enabled || IS_ENABLED(CONFIG_TEST_COUNTER));
}
```

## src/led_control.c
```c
/* Copyright (c) 2022 Nordic Semiconductor ASA
 *
 * SPDX-License-Identifier: LicenseRef-Nordic-5-Clause
 */
#include <zephyr/kernel.h>
#include <zephyr/logging/log.h>
#include <zephyr/drivers/led.h>
#include <stdlib.h>

#include "led_control.h"

/* We implement, here, both 4-led and RGB LED control, but you may feel free to implement
 * whatever your board can support. You must make sure your board Device Tree Source or overlays
 * include a device marked as compatible with either the pwm-leds or gpio-leds driver in order to
 * use the LED driver provided by Zephyr, as we do here.
 */

LOG_MODULE_REGISTER(led_control, CONFIG_WIFI_NRF_CLOUD_LOG_LEVEL);

/* Find a Device Tree node compatible with either the pwm_leds or gpio_leds driver, depending on
 * what has been configured.
 */
#if defined(CONFIG_LED_INDICATION_PWM)
const static struct device *led_device = DEVICE_DT_GET_ANY(pwm_leds);
#elif defined(CONFIG_LED_INDICATION_GPIO)
const static struct device *led_device = DEVICE_DT_GET_ANY(gpio_leds);
#else
const static struct device *led_device;
#endif

#define LED_RGB_R 0
#define LED_RGB_G 1
#define LED_RGB_B 2

#define LED_4LED_1 0
#define LED_4LED_2 1
#define LED_4LED_3 2
#define LED_4LED_4 3

/**
 * @brief If the LED mode is 4 binary LEDs, set the LED state
 *
 * @param l1 - LED 1 on?
 * @param l2 - LED 2 on?
 * @param l3 - LED 3 on?
 * @param l4 - LED 4 on?
 */
static void led_set_4led(bool l1, bool l2, bool l3, bool l4)
{
	led_set_brightness(led_device, LED_4LED_1, l1 ? 100 : 0);
	led_set_brightness(led_device, LED_4LED_2, l2 ? 100 : 0);
	led_set_brightness(led_device, LED_4LED_3, l3 ? 100 : 0);
	led_set_brightness(led_device, LED_4LED_4, l4 ? 100 : 0);
}

/**
 * @brief If the LED mode is RGB, set the RGB values.
 *
 * @param r - LED Red channel.
 * @param g - LED Green channel.
 * @param b - LED Blue channel.
 */
static void led_set_rgb(int r, int g, int b)
{
	led_set_brightness(led_device, LED_RGB_R, r);
	led_set_brightness(led_device, LED_RGB_G, g);
	led_set_brightness(led_device, LED_RGB_B, b);
}

/**
 * @brief Change the LEDs to a pattern that indicates success.
 *
 * @param frame_number - An integer used for basic animations.
 */
static void led_pattern_success(int frame_number)
{
	/* Square wave with period 12 frames and duty cycle 25% */
	bool blink = (frame_number % 12) < 3;

	if (IS_ENABLED(CONFIG_LED_INDICATOR_RGB)) {
		/* Blink the green channel */
		led_set_rgb(0, blink ? 100 : 0, 0);
	} else if (IS_ENABLED(CONFIG_LED_INDICATOR_4LED)) {
		/* Blink alternating diagonals on a 4LED square */
		led_set_4led(blink, !blink, !blink, blink);
	}
}

/**
 * @brief Change the LEDs to a pattern that indicates failure.
 *
 * @param frame_number - An integer used for basic animations.
 */
static void led_pattern_failure(int frame_number)
{
	/* Square wave with period 20 frames and duty cycle 75% */
	int blink = (frame_number % 20) < 15;

	if (IS_ENABLED(CONFIG_LED_INDICATOR_RGB)) {
		/* Blink red channel */
		led_set_rgb(blink ? 100 : 0, 0, 0);
	} else if (IS_ENABLED(CONFIG_LED_INDICATOR_4LED)) {
		/* Blink all four LEDs */
		led_set_4led(blink, blink, blink, blink);
	}
}

/**
 * @brief Change the LEDs to a pattern that indicates no relevant activity.
 *
 * @param frame_number - An integer used for basic animations.
 */
static void led_pattern_idle(int frame_number)
{
	if (IS_ENABLED(CONFIG_LED_INDICATOR_RGB)) {
		/* A triangle wave between 0 and 20 */
		int breath = abs((frame_number % 40) - 20);

		/* Breathe back and forth between cyan and pure blue */
		led_set_rgb(0, breath, 20);
	} else if (IS_ENABLED(CONFIG_LED_INDICATOR_4LED)) {
		/* Square wave with period 40 frames and duty cycle 50% */
		bool blink = (frame_number % 40) < 20;

		/* Blink between two LEDs on opposite sides of a diagonal, of the 4LED square,
		 * namely "LED1" and "LED4" on 91 Series DK boards
		 */
		led_set_4led(blink, false, false, !blink);
	}
}

/**
 * @brief Change the LEDs to a pattern that indicates waiting.
 *
 * @param frame_number - An integer used for basic animations.
 */
static void led_pattern_waiting(int frame_number)
{
	if (IS_ENABLED(CONFIG_LED_INDICATOR_RGB)) {
		/* A triangle wave between 0 and 10 */
		int breath = abs((frame_number % 20) - 10);

		/* Pulsating orange */
		led_set_rgb(breath * 10, breath, 0);
	} else if (IS_ENABLED(CONFIG_LED_INDICATOR_4LED)) {
		/* Spin a single LED around the 4LED square */
		led_set_4led((frame_number % 4) == 0,
			     (frame_number % 4) == 1,
			     (frame_number % 4) == 3,
			     (frame_number % 4) == 2);
	}
}

/**
 * @brief Disable the LEDs.
 */
static void led_pattern_disabled(void)
{
	if (IS_ENABLED(CONFIG_LED_INDICATOR_RGB)) {
		led_set_rgb(0, 0, 0);
	} else if (IS_ENABLED(CONFIG_LED_INDICATOR_4LED)) {
		led_set_4led(false, false, false, false);
	}
}

/* Zephyr event for signaling cross-thread when an LED pattern has been requested */
#define LED_PATTERN_REQUESTED (1 << 1)
static K_EVENT_DEFINE(led_events);

/* The currently requested pattern, frames of it remaining, and total number of frames it has
 * been executed for. Negative frames remaining indicates an indefinite effect.
 */
atomic_t requested_pattern = LED_DISABLED;
atomic_t requested_pattern_frames_remaining = -1;
atomic_t requested_pattern_animation_frame;

void start_led_pattern(int frames, enum led_pattern pattern)
{
	if (!IS_ENABLED(CONFIG_LED_INDICATION_DISABLED)) {
		atomic_set(&requested_pattern, pattern);
		atomic_set(&requested_pattern_frames_remaining, frames);
		atomic_set(&requested_pattern_animation_frame, 0);
		k_event_post(&led_events, LED_PATTERN_REQUESTED);
		LOG_DBG("LED Pattern Requested");
	}
}

static K_TIMER_DEFINE(led_animate_timer, NULL, NULL);
/**
 * @brief Display a single frame of a specified pattern
 *
 * @param frame_number - The frame number to show.
 * @param led_pattern - The pattern to show.
 */
static void animate_leds_frame(int frame_number, enum led_pattern pattern)
{
	/* Wait for the timer from the previous call to this function to expire, and then
	 * immediately restart the timer.
	 * This guarantees that this function completes, at most, once every frame interval
	 */

	k_timer_status_sync(&led_animate_timer);
	k_timer_start(&led_animate_timer, K_MSEC(100), K_FOREVER);

	/* Run a single frame of the pattern */
	switch (pattern) {
	case LED_IDLE:
		led_pattern_idle(frame_number);
		break;
	case LED_WAITING:
		led_pattern_waiting(frame_number);
		break;
	case LED_FAILURE:
		led_pattern_failure(frame_number);
		break;
	case LED_SUCCESS:
		led_pattern_success(frame_number);
		break;
	default:
		led_pattern_disabled();
	}
}

void led_animation_thread_fn(void)
{
	LOG_DBG("LED Management Started");

	if (!device_is_ready(led_device)) {
		LOG_ERR("No LED device found, cancelling LED indication.");
		return;
	}

	/* Self-request an initial LED update, using the default state, or otherwise keeping what
	 * any pre-existing thread already requested.
	 */
	k_event_post(&led_events, LED_PATTERN_REQUESTED);

	while (true) {
		/* Wait for a pattern to be started */
		(void)k_event_wait(&led_events, LED_PATTERN_REQUESTED, false, K_FOREVER);

		LOG_DBG("LED Pattern Started");
		while (true) {
			/* Decrement frames remaining, and exit if we hit zero, or if
			 * the requested pattern is LED_DISABLED.
			 *
			 * Negative values will indefinitely decrement without hitting zero.
			 */
			int pattern = atomic_get(&requested_pattern);
			int fr = atomic_dec(&requested_pattern_frames_remaining);

			if (fr == 0 || pattern == LED_DISABLED) {
				break;
			}

			/* Perform an animation frame, incrementing the current animation frame
			 * counter. Note that LED_DISABLED will never be performed by this call,
			 * since that pattern causes us to break out of the loop above.
			 */
			animate_leds_frame(atomic_inc(&requested_pattern_animation_frame), pattern);
		}

		/* The pattern has ended, clear the pattern event flag so that a new one can
		 * be requested.
		 */
		k_event_set(&led_events, 0);

		/* Either switch to the IDLE pattern, or disable LEDs without activating a new
		 * pattern, depending on whether continuous indication is requested.
		 */
		if (IS_ENABLED(CONFIG_LED_CONTINUOUS_INDICATION)) {
			long_led_pattern(LED_IDLE);
		} else {
			animate_leds_frame(0, LED_DISABLED);
		}

		LOG_DBG("LED Pattern Ended");
	}
}

void long_led_pattern(enum led_pattern pattern)
{
	start_led_pattern(-1, pattern);
}

void short_led_pattern(enum led_pattern pattern)
{
	start_led_pattern(30, pattern);
}

void stop_led_pattern(void)
{
	short_led_pattern(LED_DISABLED);
}
```

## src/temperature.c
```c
/* Copyright (c) 2022 Nordic Semiconductor ASA
 *
 * SPDX-License-Identifier: LicenseRef-Nordic-5-Clause
 */

#include <zephyr/kernel.h>
#include <zephyr/logging/log.h>

#if CONFIG_TEMP_DATA_USE_SENSOR

#include <zephyr/devicetree.h>
#include <zephyr/drivers/sensor.h>

#else /* CONFIG_TEMP_DATA_USE_SENSOR */

#include <zephyr/random/random.h>

#endif /* CONFIG_TEMP_DATA_USE_SENSOR */

#include "temperature.h"

LOG_MODULE_REGISTER(temperature, CONFIG_WIFI_NRF_CLOUD_LOG_LEVEL);

#if CONFIG_TEMP_DATA_USE_SENSOR

static const struct device *temp_sensor = DEVICE_DT_GET(DT_ALIAS(temp_sensor));

int get_temperature(double *temp)
{
	int err;
	struct sensor_value data = {0};

	/* Fetch all data the sensor supports. */
	err = sensor_sample_fetch_chan(temp_sensor, SENSOR_CHAN_ALL);
	if (err) {
		LOG_ERR("Failed to sample temperature sensor, error %d", err);
		return -ENODATA;
	}

	/* Pick out the ambient temperature data. */
	err = sensor_channel_get(temp_sensor, SENSOR_CHAN_AMBIENT_TEMP, &data);
	if (err) {
		LOG_ERR("Failed to read temperature, error %d", err);
		return -ENODATA;
	}

	*temp = sensor_value_to_double(&data);

	return 0;
}

#else /* CONFIG_TEMP_DATA_USE_SENSOR */

int get_temperature(double *temp)
{
	*temp = 22.0 + (sys_rand32_get() % 100) / 40.0;
	return 0;
}

#endif /* CONFIG_TEMP_DATA_USE_SENSOR */
```
